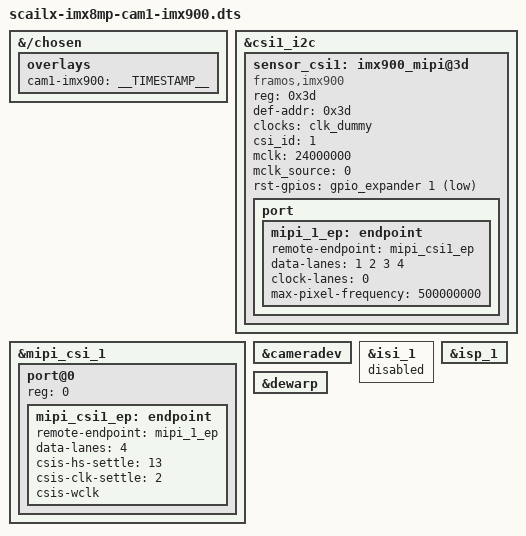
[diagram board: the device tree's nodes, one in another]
// SPDX-License-Identifier: (GPL-2.0 OR MIT)
/*
 * Copyright (C) 2023 VideologyInc
 *
 */

/dts-v1/;
/plugin/;

#include <dt-bindings/clock/imx8mp-clock.h>
#include <dt-bindings/gpio/gpio.h>

&{/chosen} {
	overlays {
		cam1-imx900 = __TIMESTAMP__;
	};
};

&csi1_i2c {
	#address-cells = <1>;
	#size-cells = <0>;

	sensor_csi1: imx900_mipi@3d {
		compatible = "framos,imx900";
		reg = <0x3d>;
		def-addr = <0x3d>;
		clocks = <&clk_dummy>;
		clock-names = "csi_mclk";
		csi_id = <1>;
		mclk = <24000000>;
		mclk_source = <0>;
		status = "okay";
		rst-gpios = <&gpio_expander 1 GPIO_ACTIVE_LOW>;

		port {
			mipi_1_ep: endpoint {
				remote-endpoint = <&mipi_csi1_ep>;
				data-lanes = <1 2 3 4>;
				clock-lanes = <0>;
				max-pixel-frequency = /bits/ 64 <500000000>;
			};
		};
	};
};

&mipi_csi_1 {
	status = "okay";
	#address-cells = <1>;
	#size-cells = <0>;

	port@0 {
		reg = <0>;
		mipi_csi1_ep: endpoint {
			remote-endpoint = <&mipi_1_ep>;
			data-lanes = <4>;
			csis-hs-settle = <13>;
			csis-clk-settle = <2>;
			csis-wclk;
		};
	};
};

&cameradev {
	status = "okay";
};

&isi_1 {
	status = "disabled";
};

&isp_1 {
	status = "okay";
};

&dewarp {
	status = "okay";
};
